# TLSR826X register map
File version: 0.1
Registers are 8-bit, access not given, no defined reset value unless marked. A register's access mark holds for its fields unless they carry their own. Offsets are from the block's base; [hi:lo] are bit positions; {n}, {i} and the like mark numbered series.

## SWIRE — Auto-generated from section 'swire'
Base 0x008000B0
0x00 SWIRE_DATA — Auto-generated from swire_data
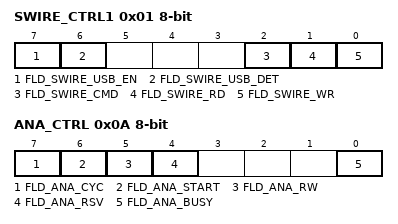
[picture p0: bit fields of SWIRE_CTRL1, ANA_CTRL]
0x01 SWIRE_CTRL1 — Auto-generated from swire_ctrl1
  [7] FLD_SWIRE_USB_EN, [6] FLD_SWIRE_USB_DET, [2] FLD_SWIRE_CMD, [1] FLD_SWIRE_RD, [0] FLD_SWIRE_WR
0x02 SWIRE_CLK_DIV — Auto-generated from swire_clk_div
0x08 ANA_ADDR — Auto-generated from ana_addr
0x09 ANA_DATA — Auto-generated from ana_data
0x0A ANA_CTRL — Auto-generated from ana_ctrl
  [7] FLD_ANA_CYC, [6] FLD_ANA_START, [5] FLD_ANA_RW, [4] FLD_ANA_RSV, [0] FLD_ANA_BUSY

## DMA_MAC — Auto-generated from section 'dma mac'
Base 0x00800500
{0x0+4i} DMA{i}_ADDR 16-bit (i=0..5) — Auto-generated from dma{i}_addr
{0x2+4i} DMA{i}_CTRL 16-bit (i=0..5) — Auto-generated from dma{i}_ctrl
0x20 DMA_CHN_EN — Auto-generated from dma_chn_en
0x21 DMA_CHN_IRQ_MSK — Auto-generated from dma_chn_irq_msk
0x24 DMA_TX_RDY0 — Auto-generated from dma_tx_rdy0
0x25 DMA_TX_RDY1 — Auto-generated from dma_tx_rdy1
0x26 DMA_RX_RDY0 — Auto-generated from dma_rx_rdy0
0x27 DMA_RX_RDY1 — Auto-generated from dma_rx_rdy1
  [3] FLD_DMA_CHN_RF_TX, [3] FLD_DMA_RF_TX, [2] FLD_DMA_CHN_RF_RX, [2] FLD_DMA_RF_RX, [1] FLD_DMA_CHN_UART_TX, [1] FLD_DMA_UART_TX, [0] FLD_DMA_CHN_UART_RX, [0] FLD_DMA_UART_RX
0x28 DMA_RX_RPTR — Auto-generated from dma_rx_rptr
0x29 DMA_RX_WPTR — Auto-generated from dma_rx_wptr
0x2A DMA_TX_RPTR — Auto-generated from dma_tx_rptr
0x2B DMA_TX_WPTR — Auto-generated from dma_tx_wptr
0x2C DMA_TX_FIFO 16-bit — Auto-generated from dma_tx_fifo
  [12] FLD_DMA_BYTE_MODE, [11] FLD_DMA_AUTO_MODE, [10] FLD_DMA_FIFO_EN, [9] FLD_DMA_PINGPONG_EN, [8] FLD_DMA_WR_MEM, [6] FLD_DMA_RPTR_SET, [5] FLD_DMA_RPTR_NEXT, [4] FLD_DMA_RPTR_CLR, [7:0] FLD_DMA_BUF_SIZE
0x40 AES_CTRL — Auto-generated from aes_ctrl
0x48 AES_DATA 32-bit — Auto-generated from aes_data
{0x50+i} AES_KEY{i} (i=0..15) — Auto-generated from aes_key{i}

## TIMER — Auto-generated from section 'timer'
Base 0x00800620
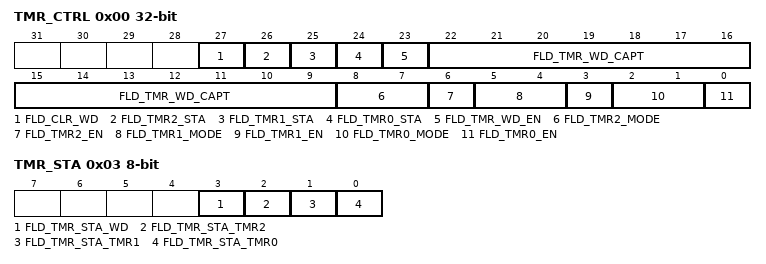
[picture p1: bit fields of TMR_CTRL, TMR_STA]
0x00 TMR_CTRL 32-bit — Auto-generated from tmr_ctrl; aliases: TMR_CTRL16, TMR_CTRL8
  [27] FLD_CLR_WD, [26] FLD_TMR2_STA, [25] FLD_TMR1_STA, [24] FLD_TMR0_STA, [23] FLD_TMR_WD_EN, [22:9] FLD_TMR_WD_CAPT, [8:7] FLD_TMR2_MODE, [6] FLD_TMR2_EN, [5:4] FLD_TMR1_MODE, [3] FLD_TMR1_EN, [2:1] FLD_TMR0_MODE, [0] FLD_TMR0_EN
0x03 TMR_STA — Auto-generated from tmr_sta
  [3] FLD_TMR_STA_WD, [2] FLD_TMR_STA_TMR2, [1] FLD_TMR_STA_TMR1, [0] FLD_TMR_STA_TMR0
{0x4+4i} TMR{i}_CAPT 32-bit (i=0..2) — Auto-generated from tmr{i}_capt
{0x10+4i} TMR{i}_TICK 32-bit (i=0..2) — Auto-generated from tmr{i}_tick

## INTERRUPT — Auto-generated from section 'interrupt'
Base 0x00800640
0x00 IRQ_MASK 32-bit — Auto-generated from irq_mask
0x03 IRQ_EN — Auto-generated from irq_en
0x04 IRQ_PRI 32-bit — Auto-generated from irq_pri
0x08 IRQ_SRC 32-bit — Auto-generated from irq_src
  [31:24] FLD_IRQ_EN, [23] FLD_IRQ_GPIO_RISC2_EN, [22] FLD_IRQ_GPIO_RISC1_EN, [21] FLD_IRQ_GPIO_RISC0_EN, [20] FLD_IRQ_SYSTEM_TIMER, [19] FLD_IRQ_PM_EN, [18] FLD_IRQ_GPIO_EN, [17] FLD_IRQ_USB_RST_EN, [16] FLD_IRQ_USB_250US_EN, [15] FLD_IRQ_AN_EN, [14] FLD_IRQ_SW_EN, [13] FLD_IRQ_ZB_RT_EN, [12] FLD_IRQ_EP_DATA_EN, [12] FLD_IRQ_IRQ4_EN, [11] FLD_IRQ_SET_INTF_EN, [10] FLD_IRQ_EP0_STA_EN, [9] FLD_IRQ_EP0_DAT_EN, [8] FLD_IRQ_EP0_SETUP_EN, [7] FLD_IRQ_HOST_CMD_EN, [6] FLD_IRQ_UART_EN, [5] FLD_IRQ_DAM_FIFO_EN, [4] FLD_IRQ_DMA_EN, [3] FLD_IRQ_USB_PWDN_EN, [2] FLD_IRQ_TMR2_EN, [1] FLD_IRQ_TMR1_EN, [0] FLD_IRQ_TMR0_EN
0x0A IRQ_SRC3 — Auto-generated from irq_src3
0x100 SYSTEM_TICK 32-bit — Auto-generated from system_tick
0x104 SYSTEM_TICK_IRQ 32-bit — Auto-generated from system_tick_irq
0x108 SYSTEM_WAKEUP_TICK 32-bit — Auto-generated from system_wakeup_tick
0x10C SYSTEM_TICK_MODE — Auto-generated from system_tick_mode
0x10F SYSTEM_TICK_CTRL — Auto-generated from system_tick_ctrl
  [1] FLD_SYSTEM_TICK_IRQ_EN, [1] FLD_SYSTEM_TICK_RUNNING, [1] FLD_SYSTEM_TICK_STOP, [0] FLD_SYSTEM_TICK_START

## PWM — Auto-generated from section 'PWM'
Base 0x00800780
0x00 PWM_ENABLE — Auto-generated from pwm_enable
0x01 PWM_CLK — Auto-generated from pwm_clk
0x02 PWM_MODE — Auto-generated from pwm_mode
0x03 PWM_INVERT — Auto-generated from pwm_invert
0x04 PWM_N_INVERT — Auto-generated from pwm_n_invert
0x05 PWM_POL — Auto-generated from pwm_pol
0x30 PWM_IRQ_MASK — Auto-generated from pwm_irq_mask
0x31 PWM_IRQ_STA — Auto-generated from pwm_irq_sta
{0x80+0x100*i} FIFO{i}_DATA 32-bit (i=0..2) — Auto-generated from fifo{i}_data
0x8C PWM_PNUM0 16-bit — Auto-generated from pwm_pnum0
0x8E PWM_PNUM1 16-bit — Auto-generated from pwm_pnum1
